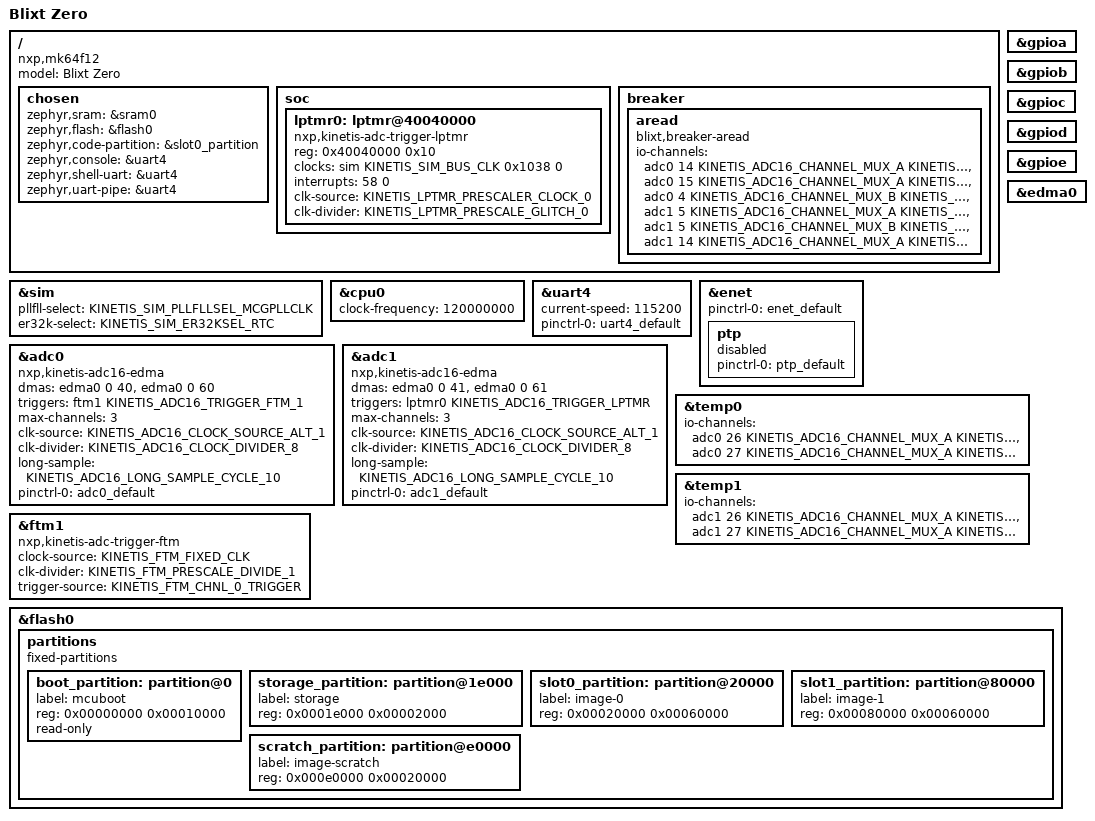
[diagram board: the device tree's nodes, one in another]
/dts-v1/;

#include <nxp/nxp_k6x.dtsi>
#include <dt-bindings/adc/kinetis-adc.h>
#include <dt-bindings/timer/kinetis-lptmr.h>
#include <dt-bindings/timer/kinetis-ftm.h>
#include "zero-pinctrl.dtsi"

/ {
	model = "Blixt Zero";
	compatible = "nxp,mk64f12", "nxp,k64f", "nxp,k6x";

	chosen {
		zephyr,sram = &sram0;
		zephyr,flash = &flash0;
		zephyr,code-partition = &slot0_partition;
		zephyr,console = &uart4;
		zephyr,shell-uart = &uart4;
		zephyr,uart-pipe = &uart4;
	};

	soc {
		/* LPTMR is not in nxp_k6x.dtsi. */
		lptmr0: lptmr@40040000 {
			compatible = "nxp,kinetis-adc-trigger-lptmr";
			reg = <0x40040000 0x10>;
			clocks = <&sim KINETIS_SIM_BUS_CLK 0x1038 0>;
			interrupts = <58 0>;
			clk-source = <KINETIS_LPTMR_PRESCALER_CLOCK_0>; /* MCGIRCLK */
			clk-divider = <KINETIS_LPTMR_PRESCALE_GLITCH_0>; /* divide by 2 */
			#trigger-cells = <1>;
		};
	};

	breaker {
		aread: aread {
			compatible = "blixt,breaker-aread";
			io-channels = <&adc0 14 KINETIS_ADC16_CHANNEL_MUX_A KINETIS_ADC16_CHANNEL_TYPE_SE>, /* I_LOW_GAIN */
				<&adc0 15 KINETIS_ADC16_CHANNEL_MUX_A KINETIS_ADC16_CHANNEL_TYPE_SE>, /* I_HIGH_GAIN */
				<&adc0 4  KINETIS_ADC16_CHANNEL_MUX_B KINETIS_ADC16_CHANNEL_TYPE_SE>, /* V_MAINS */
				<&adc1 5  KINETIS_ADC16_CHANNEL_MUX_A KINETIS_ADC16_CHANNEL_TYPE_SE>, /* T_MOSFET_IN */
				<&adc1 5  KINETIS_ADC16_CHANNEL_MUX_B KINETIS_ADC16_CHANNEL_TYPE_SE>, /* T_MOSFET_OUT */
				<&adc1 14 KINETIS_ADC16_CHANNEL_MUX_A KINETIS_ADC16_CHANNEL_TYPE_SE>; /* T_AMBIENT */
			io-channel-names = "I_LOW_GAIN",
					"I_HIGH_GAIN",
					"V_MAINS",
					"T_MOSFET_IN",
					"T_MOSFET_OUT",
					"T_AMBIENT";
		};
	};
};

&sim {
	pllfll-select = <KINETIS_SIM_PLLFLLSEL_MCGPLLCLK>;
	er32k-select = <KINETIS_SIM_ER32KSEL_RTC>;
};

&cpu0 {
	clock-frequency = <120000000>;
};

&gpioa {
	status = "okay";
};

&gpiob {
	status = "okay";
};

&gpioc {
	status = "okay";
};

&gpiod {
	status = "okay";
};

&gpioe {
	status = "okay";
};

&edma0 {
	status = "okay";
};

&uart4 {
	current-speed = <115200>;
	pinctrl-0 = <&uart4_default>;
	pinctrl-names = "default";
	status = "okay";
};

&enet {
	pinctrl-0 = <&enet_default>;
	pinctrl-names = "default";
	ptp {
		/* Be aware that PTC16 and PTC17 are also used for uart3 */
		status = "disabled";
		pinctrl-0 = <&ptp_default>;
		pinctrl-names = "default";
	};
	status = "okay";
};

&adc0 {
	compatible = "nxp,kinetis-adc16-edma";
	dmas = <&edma0 0 40>, <&edma0 0 60>; /* Format: <dma_instance, multiplexer, source> */
	dma-names = "RESULT", "CHANNEL";
	triggers = <&ftm1 KINETIS_ADC16_TRIGGER_FTM_1>;
	max-channels = <3>;
	clk-source = <KINETIS_ADC16_CLOCK_SOURCE_ALT_1>;
	clk-divider = <KINETIS_ADC16_CLOCK_DIVIDER_8>;
	long-sample = <KINETIS_ADC16_LONG_SAMPLE_CYCLE_10>;
	pinctrl-0 = <&adc0_default>;
	pinctrl-names = "default";
	status = "okay";
	#io-channel-cells = <3>;
};

&adc1 {
	compatible = "nxp,kinetis-adc16-edma";
	dmas = <&edma0 0 41>, <&edma0 0 61>; /* Format: <dma_instance, multiplexer, source> */
	dma-names = "RESULT", "CHANNEL";
	triggers = <&lptmr0 KINETIS_ADC16_TRIGGER_LPTMR>;
	max-channels = <3>;
	clk-source = <KINETIS_ADC16_CLOCK_SOURCE_ALT_1>;
	clk-divider = <KINETIS_ADC16_CLOCK_DIVIDER_8>;
	long-sample = <KINETIS_ADC16_LONG_SAMPLE_CYCLE_10>;
	pinctrl-0 = <&adc1_default>;
	pinctrl-names = "default";
	status = "okay";
	#io-channel-cells = <3>;
};


&temp0 {
	io-channels = <&adc0 26 KINETIS_ADC16_CHANNEL_MUX_A KINETIS_ADC16_CHANNEL_TYPE_SE>,
		<&adc0 27 KINETIS_ADC16_CHANNEL_MUX_A KINETIS_ADC16_CHANNEL_TYPE_SE>;
	io-channel-names = "SENSOR", "BANDGAP";
};


&temp1 {
	io-channels = <&adc1 26 KINETIS_ADC16_CHANNEL_MUX_A KINETIS_ADC16_CHANNEL_TYPE_SE>,
		<&adc1 27 KINETIS_ADC16_CHANNEL_MUX_A KINETIS_ADC16_CHANNEL_TYPE_SE>;
	io-channel-names = "SENSOR", "BANDGAP";
};


&ftm1 {
	compatible = "nxp,kinetis-adc-trigger-ftm";
	clock-source = <KINETIS_FTM_FIXED_CLK>;
	clk-divider = <KINETIS_FTM_PRESCALE_DIVIDE_1>;
	trigger-source = <KINETIS_FTM_CHNL_0_TRIGGER>;
	#trigger-cells = <1>;
	status = "okay";
};

&lptmr0 {
	status = "okay";
};

&flash0 {
	/*
	* For more information, see:
	* http://docs.zephyrproject.org/latest/guides/dts/index.html#flash-partitions
	*/
	partitions {
		compatible = "fixed-partitions";
		#address-cells = <1>;
		#size-cells = <1>;

		boot_partition: partition@0 {
			label = "mcuboot";
			reg = <0x00000000 0x00010000>;
			read-only;
		};

		/*
		* The flash starting at 0x00010000 and ending at
		* 0x0001ffff (sectors 16-31) is reserved for use
		* by the application.
		*/
		storage_partition: partition@1e000 {
			label = "storage";
			reg = <0x0001e000 0x00002000>;
		};

		slot0_partition: partition@20000 {
			label = "image-0";
			reg = <0x00020000 0x00060000>;
		};
		slot1_partition: partition@80000 {
			label = "image-1";
			reg = <0x00080000 0x00060000>;
		};
		scratch_partition: partition@e0000 {
			label = "image-scratch";
			reg = <0x000e0000 0x00020000>;
		};
	};
};
